VERSION ""

NS_ :

BS_:

BU_: HMI_ECU TPMS_ECU Engine_ECU

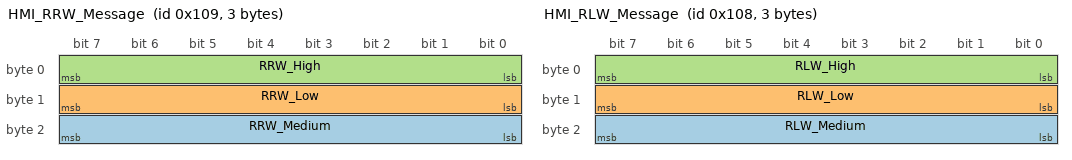
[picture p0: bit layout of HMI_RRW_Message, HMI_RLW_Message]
BO_ 265 HMI_RRW_Message: 3 Vector__XXX
 SG_ RRW_Medium : 16|8@1+ (1,0) [0|1] "" Vector__XXX
 SG_ RRW_Low : 8|8@1+ (1,0) [0|1] "" Vector__XXX
 SG_ RRW_High : 0|8@1+ (1,0) [0|1] "" Vector__XXX

BO_ 264 HMI_RLW_Message: 3 Vector__XXX
 SG_ RLW_Medium : 16|8@1+ (1,0) [0|1] "" Vector__XXX
 SG_ RLW_Low : 8|8@1+ (1,0) [0|1] "" Vector__XXX
 SG_ RLW_High : 0|8@1+ (1,0) [0|1] "" Vector__XXX

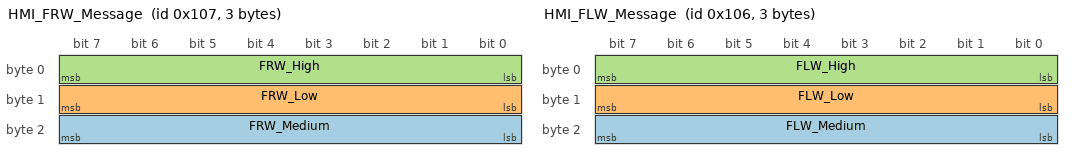
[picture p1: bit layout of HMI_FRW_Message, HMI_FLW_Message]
BO_ 263 HMI_FRW_Message: 3 Vector__XXX
 SG_ FRW_Medium : 16|8@1+ (1,0) [0|1] "" Vector__XXX
 SG_ FRW_Low : 8|8@1+ (1,0) [0|1] "" Vector__XXX
 SG_ FRW_High : 0|8@1+ (1,0) [0|1] "" Vector__XXX

BO_ 262 HMI_FLW_Message: 3 Vector__XXX
 SG_ FLW_Medium : 16|8@1+ (1,0) [0|1] "" Vector__XXX
 SG_ FLW_Low : 8|8@1+ (1,0) [0|1] "" Vector__XXX
 SG_ FLW_High : 0|8@1+ (1,0) [0|1] "" Vector__XXX

BO_ 261 RRW_Message: 1 TPMS_ECU
 SG_ RRW_Signal : 0|8@1+ (1,0) [0|32] ""  HMI_ECU

BO_ 260 RLW_Message: 1 TPMS_ECU
 SG_ RLW_Signal : 0|8@1+ (1,0) [0|32] ""  HMI_ECU

BO_ 259 FRW_Message: 1 TPMS_ECU
 SG_ FRW_Signal : 0|8@1+ (1,0) [0|32] ""  HMI_ECU

BO_ 258 FLW_Message: 1 TPMS_ECU
 SG_ FLW_Signal : 0|8@1+ (1,0) [0|32] ""  HMI_ECU

BO_ 257 Engine_Message: 1 Engine_ECU
 SG_ Engine_Signal : 0|8@1+ (1,0) [0|1] ""  HMI_ECU,TPMS_ECU

EV_ Env_RRW: 0 [0|54] "" 0 1 DUMMY_NODE_VECTOR0 Vector__XXX;

EV_ Env_RLW: 0 [0|54] "" 0 2 DUMMY_NODE_VECTOR0 Vector__XXX;

EV_ Env_FRW: 0 [0|50] "" 0 3 DUMMY_NODE_VECTOR0 Vector__XXX;

EV_ Env_Engine: 0 [0|1] "" 0 4 DUMMY_NODE_VECTOR0 Vector__XXX;

EV_ Env_FLW: 0 [0|50] "" 0 5 DUMMY_NODE_VECTOR0 Vector__XXX;

BA_DEF_  "BusType" STRING ;
BA_DEF_DEF_  "BusType" "CAN";
